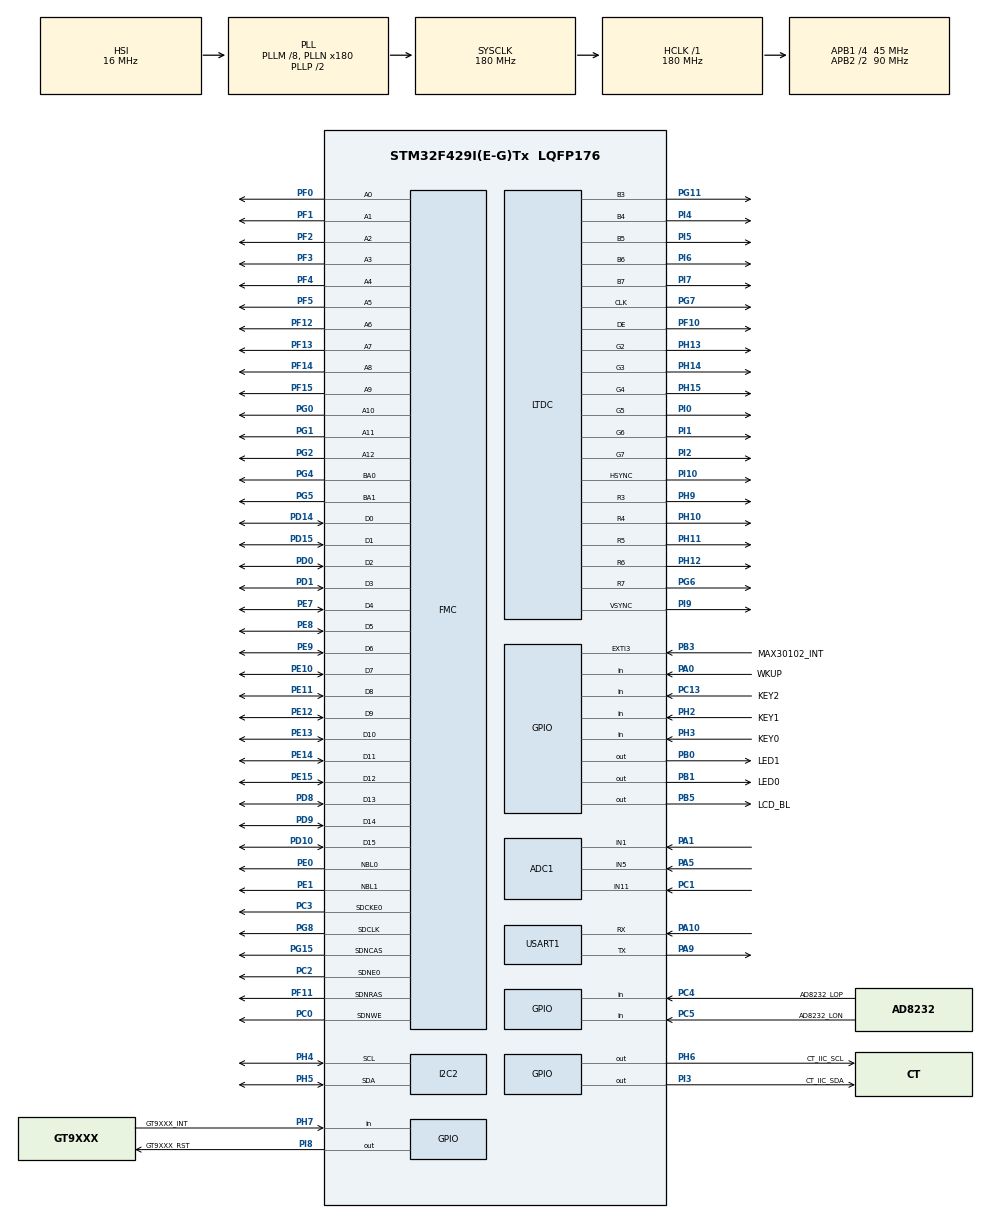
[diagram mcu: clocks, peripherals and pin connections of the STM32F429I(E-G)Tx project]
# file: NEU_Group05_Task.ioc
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ADC1.Channel-0\#ChannelRegularConversion=ADC_CHANNEL_11
ADC1.ContinuousConvMode=ENABLE
ADC1.DMAContinuousRequests=DISABLE
ADC1.ExternalTrigConv=ADC_SOFTWARE_START
ADC1.NbrOfConversionFlag=1
ADC1.Rank-0\#ChannelRegularConversion=1
ADC1.SamplingTime-0\#ChannelRegularConversion=ADC_SAMPLETIME_480CYCLES
ADC1.master=1
DMA2D.ColorMode=DMA2D_OUTPUT_RGB565
FMC.CASLatency1=FMC_SDRAM_CAS_LATENCY_3
FMC.ColumnBitsNumber1=FMC_SDRAM_COLUMN_BITS_NUM_9
FMC.ExitSelfRefreshDelay1=8
FMC.LoadToActiveDelay1=2
FMC.RCDDelay1=2
FMC.RPDelay1=2
FMC.RPDelay2=2
FMC.ReadBurst1=FMC_SDRAM_RBURST_ENABLE
FMC.ReadBurst2=FMC_SDRAM_RBURST_ENABLE
FMC.ReadPipeDelay1=FMC_SDRAM_RPIPE_DELAY_1
FMC.ReadPipeDelay2=FMC_SDRAM_RPIPE_DELAY_1
FMC.RowCycleDelay1=6
FMC.RowCycleDelay2=6
FMC.SDClockPeriod1=FMC_SDRAM_CLOCK_PERIOD_2
FMC.SDClockPeriod2=FMC_SDRAM_CLOCK_PERIOD_2
FMC.SelfRefreshTime1=6
FMC.WriteRecoveryTime1=4
FREERTOS.Mutexes01=Group05_PrtMtx,Dynamic,NULL,Available;Group05_I2C2Mtx,Dynamic,NULL,Available;Group05_SensMtx,Dynamic,NULL,Available
FREERTOS.Queues01=Group05_BuzzerQ,8,AppBuzzerRequest_t,0,Dynamic,NULL,NULL
FREERTOS.Tasks01=Group05_DefTask,24,128,StartDefaultTask,Default,NULL,Dynamic,NULL,NULL;Group05_TGFX,32,1024,TouchGFX_Task,As external,NULL,Dynamic,NULL,NULL;Group05_TInit,16,512,taskTouchInit,Default,NULL,Dynamic,NULL,NULL;Group05_Sensor,24,1024,StartTaskSensorService,As external,NULL,Dynamic,NULL,NULL;Group05_Buzzer,24,384,AppBuzzerService_Task,As external,NULL,Dynamic,NULL,NULL
FREERTOS.configLIBRARY_MAX_SYSCALL_INTERRUPT_PRIORITY=5
FREERTOS.configUSE_MUTEXES=1
LTDC.ActiveH=600
LTDC.ActiveW=1024
LTDC.Alpha_L0=255
LTDC.BlendingFactor1_L0=LTDC_BLENDING_FACTOR1_CA
LTDC.BlendingFactor2_L0=LTDC_BLENDING_FACTOR2_CA
LTDC.FBStartAdress_L0=0xC0000000
LTDC.HBP=140
LTDC.HFP=160
LTDC.HSync=20
LTDC.ImageHeight_L0=600
LTDC.ImageWidth_L0=1024
LTDC.Layers=0
LTDC.PixelFormat_L0=LTDC_PIXEL_FORMAT_RGB565
LTDC.VBP=20
LTDC.VFP=12
LTDC.VSync=3
LTDC.WindowX1_L0=1024
LTDC.WindowY1_L0=600
Mcu.Family=STM32F4
Mcu.Name=STM32F429I(E-G)Tx
Mcu.Package=LQFP176
NVIC.DMA2D_IRQn=true\:9\:0\:true\:false\:true\:true\:true\:true\:true
NVIC.EXTI3_IRQn=true\:5\:0\:false\:false\:true\:true\:true\:true\:true
NVIC.LTDC_IRQn=true\:9\:0\:true\:false\:true\:true\:true\:true\:true
NVIC.PriorityGroup=NVIC_PRIORITYGROUP_4
NVIC.TIM7_IRQn=true\:15\:0\:false\:false\:true\:false\:false\:true\:true
NVIC.TimeBase=TIM7_IRQn
NVIC.TimeBaseIP=TIM7
PA0/WKUP.GPIO_Label=WKUP
PA0/WKUP.GPIO_PuPd=GPIO_PULLDOWN
PA0/WKUP.Signal=GPIO_Input
PA1.Signal=ADCx_IN1
PA10.Mode=Asynchronous
PA10.Signal=USART1_RX
PA13.Mode=Serial_Wire
PA13.Signal=SYS_JTMS-SWDIO
PA14.Mode=Serial_Wire
PA14.Signal=SYS_JTCK-SWCLK
PA5.Signal=ADCx_IN5
PA9.Mode=Asynchronous
PA9.Signal=USART1_TX
PB0.GPIO_Label=LED1
PB0.Signal=GPIO_Output
PB1.GPIO_Label=LED0
PB1.Signal=GPIO_Output
PB3.GPIO_Label=MAX30102_INT
PB3.GPIO_ModeDefaultEXTI=GPIO_MODE_IT_FALLING
PB3.GPIO_PuPd=GPIO_PULLUP
PB3.Signal=GPXTI3
PB5.GPIO_Label=LCD_BL
PB5.PinState=GPIO_PIN_SET
PB5.Signal=GPIO_Output
PC0.Signal=FMC_SDNWE
PC1.Signal=ADCx_IN11
PC13.GPIO_Label=KEY2
PC13.GPIO_PuPd=GPIO_PULLUP
PC13.Signal=GPIO_Input
PC14/OSC32_IN.Mode=LSE-External-Oscillator
PC14/OSC32_IN.Signal=RCC_OSC32_IN
PC15/OSC32_OUT.Mode=LSE-External-Oscillator
PC15/OSC32_OUT.Signal=RCC_OSC32_OUT
PC2.Mode=SdramChipSelect1_1
PC2.Signal=FMC_SDNE0
PC3.Mode=SdramChipSelect1_1
PC3.Signal=FMC_SDCKE0
PC4.GPIO_Label=AD8232_LOP
PC4.GPIO_PuPd=GPIO_PULLDOWN
PC4.Signal=GPIO_Input
PC5.GPIO_Label=AD8232_LON
PC5.GPIO_PuPd=GPIO_PULLDOWN
PC5.Signal=GPIO_Input
PD0.Signal=FMC_D2_DA2
PD1.Signal=FMC_D3_DA3
PD10.Signal=FMC_D15_DA15
PD14.Signal=FMC_D0_DA0
PD15.Signal=FMC_D1_DA1
PD8.Signal=FMC_D13_DA13
PD9.Signal=FMC_D14_DA14
PE0.Signal=FMC_NBL0
PE1.Signal=FMC_NBL1
PE10.Signal=FMC_D7_DA7
PE11.Signal=FMC_D8_DA8
PE12.Signal=FMC_D9_DA9
PE13.Signal=FMC_D10_DA10
PE14.Signal=FMC_D11_DA11
PE15.Signal=FMC_D12_DA12
PE7.Signal=FMC_D4_DA4
PE8.Signal=FMC_D5_DA5
PE9.Signal=FMC_D6_DA6
PF0.Signal=FMC_A0
PF1.Signal=FMC_A1
PF10.GPIO_Speed=GPIO_SPEED_FREQ_VERY_HIGH
PF10.Mode=RGB565
PF10.Signal=LTDC_DE
PF11.Signal=FMC_SDNRAS
PF12.Signal=FMC_A6
PF13.Signal=FMC_A7
PF14.Signal=FMC_A8
PF15.Signal=FMC_A9
PF2.Signal=FMC_A2
PF3.Signal=FMC_A3
PF4.Signal=FMC_A4
PF5.Signal=FMC_A5
PG0.Signal=FMC_A10
PG1.Signal=FMC_A11
PG11.GPIO_Speed=GPIO_SPEED_FREQ_VERY_HIGH
PG11.Mode=RGB565
PG11.Signal=LTDC_B3
PG15.Signal=FMC_SDNCAS
PG2.Signal=FMC_A12
PG4.Signal=FMC_A14_BA0
PG5.Signal=FMC_A15_BA1
PG6.GPIO_Speed=GPIO_SPEED_FREQ_VERY_HIGH
PG6.Mode=RGB565
PG6.Signal=LTDC_R7
PG7.GPIO_Speed=GPIO_SPEED_FREQ_VERY_HIGH
PG7.Mode=RGB565
PG7.Signal=LTDC_CLK
PG8.Signal=FMC_SDCLK
PH0/OSC_IN.Mode=HSE-External-Oscillator
PH0/OSC_IN.Signal=RCC_OSC_IN
PH1/OSC_OUT.Mode=HSE-External-Oscillator
PH1/OSC_OUT.Signal=RCC_OSC_OUT
PH10.GPIO_Speed=GPIO_SPEED_FREQ_VERY_HIGH
PH10.Mode=RGB565
PH10.Signal=LTDC_R4
PH11.GPIO_Speed=GPIO_SPEED_FREQ_VERY_HIGH
PH11.Mode=RGB565
PH11.Signal=LTDC_R5
PH12.GPIO_Speed=GPIO_SPEED_FREQ_VERY_HIGH
PH12.Mode=RGB565
PH12.Signal=LTDC_R6
PH13.GPIO_Speed=GPIO_SPEED_FREQ_VERY_HIGH
PH13.Mode=RGB565
PH13.Signal=LTDC_G2
PH14.GPIO_Speed=GPIO_SPEED_FREQ_VERY_HIGH
PH14.Mode=RGB565
PH14.Signal=LTDC_G3
PH15.GPIO_Speed=GPIO_SPEED_FREQ_VERY_HIGH
PH15.Mode=RGB565
PH15.Signal=LTDC_G4
PH2.GPIO_Label=KEY1
PH2.GPIO_PuPd=GPIO_PULLUP
PH2.Signal=GPIO_Input
PH3.GPIO_Label=KEY0
PH3.GPIO_PuPd=GPIO_PULLUP
PH3.Signal=GPIO_Input
PH4.Mode=I2C
PH4.Signal=I2C2_SCL
PH5.Mode=I2C
PH5.Signal=I2C2_SDA
PH6.GPIO_Label=CT_IIC_SCL
PH6.GPIO_ModeDefaultOutputPP=GPIO_MODE_OUTPUT_OD
PH6.GPIO_PuPd=GPIO_PULLUP
PH6.Signal=GPIO_Output
PH7.GPIO_Label=GT9XXX_INT
PH7.Signal=GPIO_Input
PH9.GPIO_Speed=GPIO_SPEED_FREQ_VERY_HIGH
PH9.Mode=RGB565
PH9.Signal=LTDC_R3
PI0.GPIO_Speed=GPIO_SPEED_FREQ_VERY_HIGH
PI0.Mode=RGB565
PI0.Signal=LTDC_G5
PI1.GPIO_Speed=GPIO_SPEED_FREQ_VERY_HIGH
PI1.Mode=RGB565
PI1.Signal=LTDC_G6
PI10.GPIO_Speed=GPIO_SPEED_FREQ_VERY_HIGH
PI10.Mode=RGB565
PI10.Signal=LTDC_HSYNC
PI2.GPIO_Speed=GPIO_SPEED_FREQ_VERY_HIGH
PI2.Mode=RGB565
PI2.Signal=LTDC_G7
PI3.GPIO_Label=CT_IIC_SDA
PI3.GPIO_ModeDefaultOutputPP=GPIO_MODE_OUTPUT_OD
PI3.GPIO_PuPd=GPIO_PULLUP
PI3.Signal=GPIO_Output
PI4.GPIO_Speed=GPIO_SPEED_FREQ_VERY_HIGH
PI4.Mode=RGB565
PI4.Signal=LTDC_B4
PI5.GPIO_Speed=GPIO_SPEED_FREQ_VERY_HIGH
PI5.Mode=RGB565
PI5.Signal=LTDC_B5
PI6.GPIO_Speed=GPIO_SPEED_FREQ_VERY_HIGH
PI6.Mode=RGB565
PI6.Signal=LTDC_B6
PI7.GPIO_Speed=GPIO_SPEED_FREQ_VERY_HIGH
PI7.Mode=RGB565
PI7.Signal=LTDC_B7
PI8.GPIO_Label=GT9XXX_RST
PI8.GPIO_ModeDefaultOutputPP=GPIO_MODE_OUTPUT_PP
PI8.GPIO_PuPd=GPIO_PULLUP
PI8.Signal=GPIO_Output
PI9.GPIO_Speed=GPIO_SPEED_FREQ_VERY_HIGH
PI9.Mode=RGB565
PI9.Signal=LTDC_VSYNC
ProjectManager.HeapSize=0x200
ProjectManager.StackSize=0x400
ProjectManager.TargetToolchain=MDK-ARM V5.32
RCC.48MHZClocksFreq_Value=90000000
RCC.AHBFreq_Value=180000000
RCC.APB1CLKDivider=RCC_HCLK_DIV4
RCC.APB1Freq_Value=45000000
RCC.APB1TimFreq_Value=90000000
RCC.APB2CLKDivider=RCC_HCLK_DIV2
RCC.APB2Freq_Value=90000000
RCC.APB2TimFreq_Value=180000000
RCC.CortexFreq_Value=180000000
RCC.HCLKFreq_Value=180000000
RCC.HSE_VALUE=25000000
RCC.HSI_VALUE=16000000
RCC.PLLM=8
RCC.PLLN=180
RCC.PLLSAIN=84
RCC.RCC_RTC_Clock_Source=RCC_RTCCLKSOURCE_LSE
RCC.RCC_RTC_Clock_SourceVirtual=RCC_RTCCLKSOURCE_LSE
RCC.SYSCLKFreq_VALUE=180000000
RCC.SYSCLKSource=RCC_SYSCLKSOURCE_PLLCLK
RCC.VCOOutputFreq_Value=360000000
SH.ADCx_IN1.0=ADC1_IN1,IN1
SH.ADCx_IN11.0=ADC1_IN11,IN11
SH.ADCx_IN5.0=ADC1_IN5,IN5
SH.FMC_A0.0=FMC_A0,13b-sda1
SH.FMC_A1.0=FMC_A1,13b-sda1
SH.FMC_A10.0=FMC_A10,13b-sda1
SH.FMC_A11.0=FMC_A11,13b-sda1
SH.FMC_A12.0=FMC_A12,13b-sda1
SH.FMC_A14_BA0.0=FMC_BA0,FourSdramBanks1
SH.FMC_A15_BA1.0=FMC_BA1,FourSdramBanks1
SH.FMC_A2.0=FMC_A2,13b-sda1
SH.FMC_A3.0=FMC_A3,13b-sda1
SH.FMC_A4.0=FMC_A4,13b-sda1
SH.FMC_A5.0=FMC_A5,13b-sda1
SH.FMC_A6.0=FMC_A6,13b-sda1
SH.FMC_A7.0=FMC_A7,13b-sda1
SH.FMC_A8.0=FMC_A8,13b-sda1
SH.FMC_A9.0=FMC_A9,13b-sda1
SH.FMC_D0_DA0.0=FMC_D0,sd-16b-d1
SH.FMC_D10_DA10.0=FMC_D10,sd-16b-d1
SH.FMC_D11_DA11.0=FMC_D11,sd-16b-d1
SH.FMC_D12_DA12.0=FMC_D12,sd-16b-d1
SH.FMC_D13_DA13.0=FMC_D13,sd-16b-d1
SH.FMC_D14_DA14.0=FMC_D14,sd-16b-d1
SH.FMC_D15_DA15.0=FMC_D15,sd-16b-d1
SH.FMC_D1_DA1.0=FMC_D1,sd-16b-d1
SH.FMC_D2_DA2.0=FMC_D2,sd-16b-d1
SH.FMC_D3_DA3.0=FMC_D3,sd-16b-d1
SH.FMC_D4_DA4.0=FMC_D4,sd-16b-d1
SH.FMC_D5_DA5.0=FMC_D5,sd-16b-d1
SH.FMC_D6_DA6.0=FMC_D6,sd-16b-d1
SH.FMC_D7_DA7.0=FMC_D7,sd-16b-d1
SH.FMC_D8_DA8.0=FMC_D8,sd-16b-d1
SH.FMC_D9_DA9.0=FMC_D9,sd-16b-d1
SH.FMC_NBL0.0=FMC_NBL0,Sd2ByteEnable1
SH.FMC_NBL1.0=FMC_NBL1,Sd2ByteEnable1
SH.FMC_SDCLK.0=FMC_SDCLK,13b-sda1
SH.FMC_SDNCAS.0=FMC_SDNCAS,13b-sda1
SH.FMC_SDNRAS.0=FMC_SDNRAS,13b-sda1
SH.FMC_SDNWE.0=FMC_SDNWE,13b-sda1
STMicroelectronics.X-CUBE-TOUCHGFX.4.22.0.ApplicationCcGraphicsJjApplication=TouchGFXOoGenerator
STMicroelectronics.X-CUBE-TOUCHGFX.4.22.0.tgfx_address1=0xC0000000
STMicroelectronics.X-CUBE-TOUCHGFX.4.22.0.tgfx_address2=0xC012C000
STMicroelectronics.X-CUBE-TOUCHGFX.4.22.0.tgfx_buffering_strategy=Double
STMicroelectronics.X-CUBE-TOUCHGFX.4.22.0.tgfx_custom_height=600
STMicroelectronics.X-CUBE-TOUCHGFX.4.22.0.tgfx_display_interface=disp_ltdc
STMicroelectronics.X-CUBE-TOUCHGFX.4.22.0.tgfx_hardware_accelerator=dma_none
STMicroelectronics.X-CUBE-TOUCHGFX.4.22.0.tgfx_location=By Address
STMicroelectronics.X-CUBE-TOUCHGFX.4.22.0.tgfx_vsync=vsync_ltdc
STMicroelectronics.X-CUBE-TOUCHGFX.4.22.0_IsPackSelfContextualization=true
TIM8.Period=100 - 1
TIM8.Prescaler=18000 - 1
TIM8.TIM_MasterOutputTrigger=TIM_TRGO_UPDATE
TIM8.TIM_MasterSlaveMode=TIM_MASTERSLAVEMODE_DISABLE
USART1.VirtualMode=VM_ASYNC
VP_ADC1_TempSens_Input.Mode=IN-TempSens
VP_CRC_VS_CRC.Mode=CRC_Activate
VP_DMA2D_VS_DMA2D.Mode=DMA2D_Activate
VP_FREERTOS_VS_CMSIS_V2.Mode=CMSIS_V2
VP_RTC_VS_RTC_Activate.Mode=RTC_Enabled
VP_STMicroelectronics.X-CUBE-TOUCHGFX_VS_GraphicsJjApplication_4.22.0.Mode=GraphicsJjApplication
VP_SYS_VS_tim7.Mode=TIM7
VP_TIM8_VS_ClockSourceINT.Mode=Internal
board=custom

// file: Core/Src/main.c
/* USER CODE BEGIN Header */
/**
  ******************************************************************************
  * @file           : main.c
  * @brief          : Main program body
  ******************************************************************************
  * @attention
  *
  * Copyright (c) 2026 STMicroelectronics.
  * All rights reserved.
  *
  ******************************************************************************
  */
/* USER CODE END Header */
#include "main.h"
#include "cmsis_os.h"
#include "adc.h"
#include "crc.h"
#include "dma2d.h"
#include "i2c.h"
#include "ltdc.h"
#include "rtc.h"
#include "tim.h"
#include "usart.h"
#include "gpio.h"
#include "fmc.h"
#include "app_touchgfx.h"

/* USER CODE BEGIN Includes */
#include "delay.h"
#include <stdio.h>

/* USER CODE END Includes */

void SystemClock_Config(void);
void MX_FREERTOS_Init(void);

int main(void)
{

  /* MCU Configuration--------------------------------------------------------*/

  /* Reset of all peripherals, Initializes the Flash interface and the Systick. */
  HAL_Init();

  /* Configure the system clock */
  SystemClock_Config();

  /* USER CODE BEGIN SysInit */
  delay_init();

  /* USER CODE END SysInit */

  /* Initialize all configured peripherals */
  MX_GPIO_Init();
  MX_I2C2_Init();
  MX_USART1_UART_Init();
  MX_ADC1_Init();
  MX_TIM8_Init();
  MX_FMC_Init();
  MX_LTDC_Init();
  MX_CRC_Init();
  MX_DMA2D_Init();
  MX_RTC_Init();
  MX_TouchGFX_Init();
  /* Call PreOsInit function */
  MX_TouchGFX_PreOSInit();

  /* Init scheduler */
  osKernelInitialize();

  /* Call init function for freertos objects (in cmsis_os2.c) */
  MX_FREERTOS_Init();

  /* Start scheduler */
  osKernelStart();

  /* We should never get here as control is now taken by the scheduler */

  /* Infinite loop */
  while (1)
  {

  }
}

void SystemClock_Config(void)
{
  RCC_OscInitTypeDef RCC_OscInitStruct = {0};
  RCC_ClkInitTypeDef RCC_ClkInitStruct = {0};

  /** Configure the main internal regulator output voltage
  */
  __HAL_RCC_PWR_CLK_ENABLE();
  __HAL_PWR_VOLTAGESCALING_CONFIG(PWR_REGULATOR_VOLTAGE_SCALE1);

  /** Initializes the RCC Oscillators according to the specified parameters
  * in the RCC_OscInitTypeDef structure.
  */
  RCC_OscInitStruct.OscillatorType = RCC_OSCILLATORTYPE_HSI|RCC_OSCILLATORTYPE_LSE;
  RCC_OscInitStruct.LSEState = RCC_LSE_ON;
  RCC_OscInitStruct.HSIState = RCC_HSI_ON;
  RCC_OscInitStruct.HSICalibrationValue = RCC_HSICALIBRATION_DEFAULT;
  RCC_OscInitStruct.PLL.PLLState = RCC_PLL_ON;
  RCC_OscInitStruct.PLL.PLLSource = RCC_PLLSOURCE_HSI;
  RCC_OscInitStruct.PLL.PLLM = 8;
  RCC_OscInitStruct.PLL.PLLN = 180;
  RCC_OscInitStruct.PLL.PLLP = RCC_PLLP_DIV2;
  RCC_OscInitStruct.PLL.PLLQ = 4;
  if (HAL_RCC_OscConfig(&RCC_OscInitStruct) != HAL_OK)
  {
    Error_Handler();
  }

  /** Activate the Over-Drive mode
  */
  if (HAL_PWREx_EnableOverDrive() != HAL_OK)
  {
    Error_Handler();
  }

  /** Initializes the CPU, AHB and APB buses clocks
  */
  RCC_ClkInitStruct.ClockType = RCC_CLOCKTYPE_HCLK|RCC_CLOCKTYPE_SYSCLK
                              |RCC_CLOCKTYPE_PCLK1|RCC_CLOCKTYPE_PCLK2;
  RCC_ClkInitStruct.SYSCLKSource = RCC_SYSCLKSOURCE_PLLCLK;
  RCC_ClkInitStruct.AHBCLKDivider = RCC_SYSCLK_DIV1;
  RCC_ClkInitStruct.APB1CLKDivider = RCC_HCLK_DIV4;
  RCC_ClkInitStruct.APB2CLKDivider = RCC_HCLK_DIV2;

  if (HAL_RCC_ClockConfig(&RCC_ClkInitStruct, FLASH_LATENCY_5) != HAL_OK)
  {
    Error_Handler();
  }
}

/* USER CODE BEGIN 4 */
__WEAK void Remote_TIM_PeriodElapsedCallback(TIM_HandleTypeDef *htim)
{
  (void)htim;
}

/* USER CODE END 4 */

void HAL_TIM_PeriodElapsedCallback(TIM_HandleTypeDef *htim)
{
  if (htim->Instance == TIM7)
  {
    HAL_IncTick();
  }
  /* USER CODE BEGIN Callback 1 */
  Remote_TIM_PeriodElapsedCallback(htim);

  /* USER CODE END Callback 1 */
}

void Error_Handler(void)
{
  /* USER CODE BEGIN Error_Handler_Debug */
  /* User can add his own implementation to report the HAL error return state */
  __disable_irq();
  while (1)
  {
    HAL_GPIO_TogglePin(LED0_GPIO_Port, LED0_Pin);
    HAL_GPIO_TogglePin(LED1_GPIO_Port, LED1_Pin);
    for (volatile uint32_t i = 0; i < 2000000U; i++)
    {
    }
  }
  /* USER CODE END Error_Handler_Debug */
}

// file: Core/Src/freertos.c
/* USER CODE BEGIN Header */
/**
  ******************************************************************************
  * File Name          : freertos.c
  * Description        : Code for freertos applications
  ******************************************************************************
  * @attention
  *
  * Copyright (c) 2026 STMicroelectronics.
  * All rights reserved.
  *
  * This software is licensed under terms that can be found in the LICENSE file
  * in the root directory of this software component.
  * If no LICENSE file comes with this software, it is provided AS-IS.
  *
  ******************************************************************************
  */
/* USER CODE END Header */

#include "FreeRTOS.h"
#include "task.h"
#include "main.h"
#include "cmsis_os.h"

/* USER CODE BEGIN Includes */
#include "app_touchgfx.h"
#include "gt9xxx.h"
#include <stdarg.h>
#include <stdio.h>
#include "app_sensor_service.h"
#include "app_i2c_bus.h"
#include "app_buzzer_service.h"

/* USER CODE END Includes */

/* Definitions for Group05_DefTask */
osThreadId_t Group05_DefTaskHandle;
const osThreadAttr_t Group05_DefTask_attributes = {
  .name = "Group05_DefTask",
  .stack_size = 128 * 4,
  .priority = (osPriority_t) osPriorityNormal,
};
/* Definitions for Group05_TGFX */
osThreadId_t Group05_TGFXHandle;
const osThreadAttr_t Group05_TGFX_attributes = {
  .name = "Group05_TGFX",
  .stack_size = 1024 * 4,
  .priority = (osPriority_t) osPriorityAboveNormal,
};
/* Definitions for Group05_TInit */
osThreadId_t Group05_TInitHandle;
const osThreadAttr_t Group05_TInit_attributes = {
  .name = "Group05_TInit",
  .stack_size = 512 * 4,
  .priority = (osPriority_t) osPriorityBelowNormal,
};
/* Definitions for Group05_Sensor */
osThreadId_t Group05_SensorHandle;
const osThreadAttr_t Group05_Sensor_attributes = {
  .name = "Group05_Sensor",
  .stack_size = 1024 * 4,
  .priority = (osPriority_t) osPriorityNormal,
};
/* Definitions for Group05_Buzzer */
osThreadId_t Group05_BuzzerHandle;
const osThreadAttr_t Group05_Buzzer_attributes = {
  .name = "Group05_Buzzer",
  .stack_size = 384 * 4,
  .priority = (osPriority_t) osPriorityNormal,
};
/* Definitions for Group05_BuzzerQ */
osMessageQueueId_t Group05_BuzzerQHandle;
const osMessageQueueAttr_t Group05_BuzzerQ_attributes = {
  .name = "Group05_BuzzerQ"
};
/* Definitions for Group05_PrtMtx */
osMutexId_t Group05_PrtMtxHandle;
const osMutexAttr_t Group05_PrtMtx_attributes = {
  .name = "Group05_PrtMtx"
};
/* Definitions for Group05_I2C2Mtx */
osMutexId_t Group05_I2C2MtxHandle;
const osMutexAttr_t Group05_I2C2Mtx_attributes = {
  .name = "Group05_I2C2Mtx"
};
/* Definitions for Group05_SensMtx */
osMutexId_t Group05_SensMtxHandle;
const osMutexAttr_t Group05_SensMtx_attributes = {
  .name = "Group05_SensMtx"
};

/* USER CODE BEGIN FunctionPrototypes */
extern void TouchGFX_SignalVSync(void);
extern void TouchGFX_Touch_SetReady(uint8_t ready);
static void AppPrintf(const char *format, ...);

/* USER CODE END FunctionPrototypes */

void StartDefaultTask(void *argument);
extern void TouchGFX_Task(void *argument);
void taskTouchInit(void *argument);
extern void StartTaskSensorService(void *argument);
extern void AppBuzzerService_Task(void *argument);

void MX_FREERTOS_Init(void); /* (MISRA C 2004 rule 8.1) */

void MX_FREERTOS_Init(void) {
  /* USER CODE BEGIN Init */
  AppI2cBus_Init();
  AppBuzzerService_Init();
  /* USER CODE END Init */
  /* Create the mutex(es) */
  /* creation of Group05_PrtMtx */
  Group05_PrtMtxHandle = osMutexNew(&Group05_PrtMtx_attributes);

  /* creation of Group05_I2C2Mtx */
  Group05_I2C2MtxHandle = osMutexNew(&Group05_I2C2Mtx_attributes);

  /* creation of Group05_SensMtx */
  Group05_SensMtxHandle = osMutexNew(&Group05_SensMtx_attributes);

  /* Create the queue(s) */
  /* creation of Group05_BuzzerQ */
  Group05_BuzzerQHandle = osMessageQueueNew (8, sizeof(AppBuzzerRequest_t), &Group05_BuzzerQ_attributes);

  /* Create the thread(s) */
  /* creation of Group05_DefTask */
  Group05_DefTaskHandle = osThreadNew(StartDefaultTask, NULL, &Group05_DefTask_attributes);

  /* creation of Group05_TGFX */
  Group05_TGFXHandle = osThreadNew(TouchGFX_Task, NULL, &Group05_TGFX_attributes);

  /* creation of Group05_TInit */
  Group05_TInitHandle = osThreadNew(taskTouchInit, NULL, &Group05_TInit_attributes);

  /* creation of Group05_Sensor */
  Group05_SensorHandle = osThreadNew(StartTaskSensorService, NULL, &Group05_Sensor_attributes);

  /* creation of Group05_Buzzer */
  Group05_BuzzerHandle = osThreadNew(AppBuzzerService_Task, NULL, &Group05_Buzzer_attributes);

}

void StartDefaultTask(void *argument)
{
  /* USER CODE BEGIN StartDefaultTask */
  (void)argument;

  /* Infinite loop */
  for(;;)
  {
    osDelay(1000);
  }
  /* USER CODE END StartDefaultTask */
}

void taskTouchInit(void *argument)
{
  /* USER CODE BEGIN taskTouchInit */
  uint8_t ret;

  (void)argument;
  osDelay(300);
  AppPrintf("Touch init task start\r\n");
  ret = gt9xxx_init();
  TouchGFX_Touch_SetReady(ret);
  AppPrintf("Touch init task %s\r\n", ret == 0U ? "ok" : "fail");
  osThreadExit();
  /* USER CODE END taskTouchInit */
}

/* USER CODE BEGIN Application */
static void AppPrintf(const char *format, ...)
{
  va_list args;

  if (Group05_PrtMtxHandle != NULL)
  {
    osMutexAcquire(Group05_PrtMtxHandle, osWaitForever);
  }

  va_start(args, format);
  vprintf(format, args);
  va_end(args);

  if (Group05_PrtMtxHandle != NULL)
  {
    osMutexRelease(Group05_PrtMtxHandle);
  }
}

/* USER CODE END Application */
